# PRM_PER register map
Vendor: Texas Instruments
Peripheral module from a debugger description file (folder am335x).
Registers are 32-bit, access per field, no defined reset value unless marked. A register's access mark holds for its fields unless they carry their own. Offsets are as the file gives them; lines under a group give offsets from that group; [hi:lo] are bit positions; {n}, {i} and the like mark numbered series; 'fields as' and 'values as' point back to an identical list; <NAME> marks a mode.

## PRM_PER
0x00 RM_PER_RSTCTRL — This register controls the release of the PER Domain resets.
  [1] PRU_ICSS_LRST rw — PER domain PRU-ICSS local reset control
    0=CLEAR (Reset is cleared for the PRU-ICSS); 1=ASSERT (Reset is asserted for the PRU-ICSS)
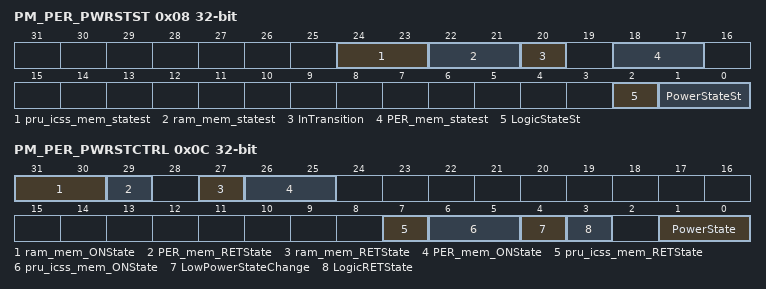
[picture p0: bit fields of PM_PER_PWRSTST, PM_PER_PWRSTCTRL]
0x08 PM_PER_PWRSTST ro — This register provides a status on the current PER power domain state. [warm reset insensitive]
  [24:23] pru_icss_mem_statest — PRU-ICSS memory state status
    0=Mem_off (Memory is OFF); 3=Mem_on (Memory is ON)
  [22:21] ram_mem_statest — OCMC RAM memory state status
    0=Mem_off (Memory is OFF); 3=Mem_on (Memory is ON)
  [20] InTransition — Domain transition status
    0=No (No on-going transition on power domain); 1=Ongoing (Power domain transition is in progress.)
  [18:17] PER_mem_statest — PER domain memory state status
    0=Mem_off (Memory is OFF); 3=Mem_on (Memory is ON)
  [2] LogicStateSt — Logic state status
    0=OFF (Logic in domain is OFF); 1=ON (Logic in domain is ON)
  [1:0] PowerStateSt — Current Power State Status
    0=OFF (OFF State); 1=RET; 3=ON (ON State)
0x0C PM_PER_PWRSTCTRL — Controls the power state of PER power domain
  [31:30] ram_mem_ONState rw — OCMC RAM memory on state
    0=OFF (Memory is OFF); 1=RET (Memory is in retention state); 3=ON (Memory is ON)
  [29] PER_mem_RETState rw — Other memories in PER Domain RET state
    0=OFF; 1=RET
  [27] ram_mem_RETState rw — OCMC RAM memory RET state
    0=OFF (Memory is in off state); 1=RET (Memory is in retention state)
  [26:25] PER_mem_ONState rw — Other memories in PER Domain ON state
    3=ON (Memory is ON)
  [7] pru_icss_mem_RETState rw — PRU-ICSS memory RET state
    values as ram_mem_RETState
  [6:5] pru_icss_mem_ONState rw — PRU-ICSS memory ON state
    3=ON (Memory is ON)
  [4] LowPowerStateChange rw — Power state change request when domain has already performed a sleep transition. Allows going into deeper low power state without waking up the power domain.
    0=DIS (Do not request a low power state change.); 1=EN (Request a low power state change. This bit is automatically cleared when the power state is effectively changed or when power state is ON.)
  [3] LogicRETState rw — Logic state when power domain is RETENTION
    0=logic_off (Only retention registers are retained and remaing logic is off when the domain is in RETENTION state.); 1=logic_ret (Whole logic is retained when domain is in RETENTION state.)
  [1:0] PowerState rw — PER domain power state control
    0=OFF; 1=RET; 3=ON
